# A31M22x register map
Vendor: ABOV Semiconductor Co., Ltd.; File version: 1.0
CPU: CM0PLUS r0p1, little endian, no MPU, no FPU, VTOR, 2 interrupt priority bits
Registers are 32-bit, read-write, reset 0x0 unless marked. A register's access mark holds for its fields unless they carry their own. Offsets are from the block's base; [hi:lo] are bit positions; {n}, {i} and the like mark numbered series; 'fields as' and 'values as' point back to an identical list.

## MPWM — Motor Pulse Width Modulation
Base 0x42001000
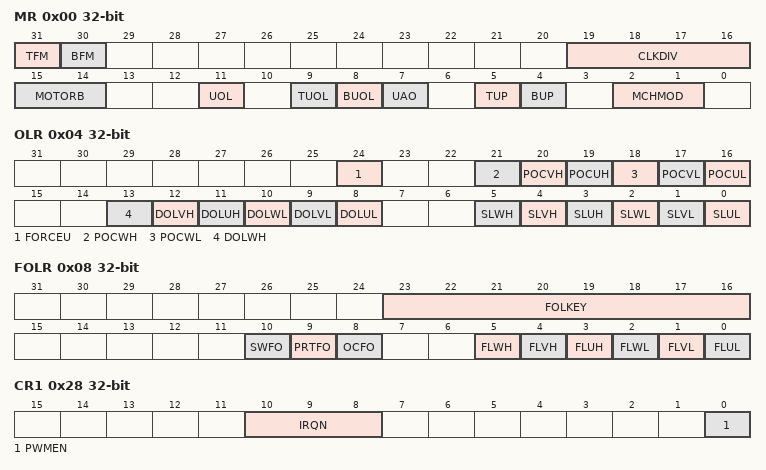
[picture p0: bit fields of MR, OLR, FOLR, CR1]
0x00 MR — MPWM Mode Register
  [31] TFM — Force Match Event at 'Full Turn Off -> PWM' in Period Match Update
    0=DISABLE (Disable force match event); 1=Enable force match event
  [30] BFM — Force Match Event at 'Full Turn On -> PWM' in Bottom Update
    values as TFM
  [19:16] CLKDIV — MPWM Clock Divider Bit, MPWM Clock = HCLK / (CLKDIV + 1)
  [15:14] MOTORB — MPWM Mode selection Bit
    0=MOTOR_PWM (Motor PWM Mode); 1=NORMAL_PWM (Normal PWM Mode)
  [11] UOL — Update Timing of Output level selection Bit
    0=DESIGNATE (Designate timing update); 1=ONCE (Once Output level Update)
  [9] TUOL — Output level Update Enable bit (When same period)
    0=None Update; 1=Update
  [8] BUOL — Output level Update Enable bit (When same bottom)
    0=None Update; 1=Update
  [7] UAO — Update Timing selection Bit
    0=DESIGNATE (Designate timing update); 1=ONCE (Once Duty Period Update)
  [5] TUP — DUTY, Period Update Enable bit (When same period)
    0=None Update; 1=Update
  [4] BUP — DUTY, Period Update Enable bit (When same bottom)
    0=None Update; 1=Update
  [2:1] MCHMOD — Channel Symmetry/Asymmetry Mode selection Bit
    0=2-ch symmetry mode; 1=1-ch asymmetry mode; 2=1-ch symmetry mode
0x04 OLR — MPWM Output Level Register
  [24] FORCEU — Phase Output selection bit
    0=6-CH (6-Channel mode); 1=Force U-Channel Mode
  [21] POCWH — PWM Output Control of WH
    0=DISABLE (PWM Output Disable); 1=ENABLE (PWM Output Enable)
  [20] POCVH — PWM Output Control of VH
    0=DISABLE (PWM Output Disable); 1=ENABLE (PWM Output Enable)
  [19] POCUH — PWM Output Control of UH
    0=DISABLE (PWM Output Disable); 1=ENABLE (PWM Output Enable)
  [18] POCWL — PWM Output Control of WL
    0=DISABLE (PWM Output Disable); 1=ENABLE (PWM Output Enable)
  [17] POCVL — PWM Output Control of VL
    0=DISABLE (PWM Output Disable); 1=ENABLE (PWM Output Enable)
  [16] POCUL — PWM Output Control of UL
    0=DISABLE (PWM Output Disable); 1=ENABLE (PWM Output Enable)
  [13] DOLWH — Output level selection bit when WH PWM Disable
    0=LOW (Low Level); 1=HIGH (High Level)
  [12] DOLVH — Output level selection bit when VH PWM Disable
    0=LOW (Low Level); 1=HIGH (High Level)
  [11] DOLUH — Output level selection bit when UH PWM Disable
    0=LOW (Low Level); 1=HIGH (High Level)
  [10] DOLWL — Output level selection bit when WL PWM Disable
    0=LOW (Low Level); 1=HIGH (High Level)
  [9] DOLVL — Output level selection bit when VL PWM Disable
    0=LOW (Low Level); 1=HIGH (High Level)
  [8] DOLUL — Output level selection bit when UL PWM Disable
    0=LOW (Low Level); 1=HIGH (High Level)
  [5] SLWH — Start Level polarity selection bit when WH PWM Start
    0=LOW (Default output level (low level)); 1=HIGH (Inverted output level (high level))
  [4] SLVH — Start Level polarity selection bit when VH PWM Start
    values as SLWH
  [3] SLUH — Start Level polarity selection bit when UH PWM Start
    values as SLWH
  [2] SLWL — Start Level polarity selection bit when WL PWM Start
    values as SLWH
  [1] SLVL — Start Level polarity selection bit when VL PWM Start
    values as SLWH
  [0] SLUL — Start Level polarity selection bit when UL PWM Start
    values as SLWH
0x08 FOLR — MPWM Forced Output Register
  [23:16] FOLKEY wo — Force output level register access key, To write a register value, the register value and the key must be used together. If the access key is not correct, the value written is ignored.
  [10] SWFO — Software force output selection bit
    0=PWM (PWM output); 1=Software (force output)
  [9] PRTFO — Protection force output bit
    0=PWM (PWM output); 1=Protection (force output)
  [8] OCFO — Over-current force output bit
    0=PWM (PWM output); 1=Over-current (force output)
  [5] FLWH — WH Force output level selection bit
    0=LOW (Force low level); 1=HIGH (Force high level)
  [4] FLVH — VH Force output level selection bit
    0=LOW (Force low level); 1=HIGH (Force level high)
  [3] FLUH — UH Force output level selection bit
    0=LOW (Force low level); 1=HIGH (Force level high)
  [2] FLWL — WL Force output level selection bit
    0=LOW (Force low level); 1=HIGH (Force level high)
  [1] FLVL — VL Force output level selection bit
    0=LOW (Force low level); 1=HIGH (Force level high)
  [0] FLUL — UL Force output level selection bit
    0=LOW (Force low level); 1=HIGH (Force level high)
0x0C PRD reset 0x2 — MPWM Period Register
  [15:0] PERIOD — 16bit pwm period
0x10 DUH reset 0x1 — MPWM DUTY UH Register
  [15:0] DUTY_UH — 16 bit PWM Duty setting bit for UH output
0x14 DVH reset 0x1 — MPWM DUTY VH Register
  [15:0] DUTY_VH — 16 bit PWM Duty setting bit for VH output
0x18 DWH reset 0x1 — MPWM DUTY WH Register
  [15:0] DUTY_WH — 16 bit PWM Duty setting bit for WH output
0x1C DUL reset 0x1 — MPWM DUTY UL Register
  [15:0] DUTY_UL — 16 bit PWM Duty setting bit for UL output
0x20 DVL reset 0x1 — MPWM DUTY VL Register
  [15:0] DUTY_VL — 16 bit PWM Duty setting bit for VL output
0x24 DWL reset 0x1 — MPWM DUTY WL Register
  [15:0] DUTY_WL — 16 bit PWM Duty setting bit for WL output
0x28 CR1 — MPWM Control Register 1
  [10:8] IRQN — IRQ number
  [0] PWMEN — PWM Enable Bit
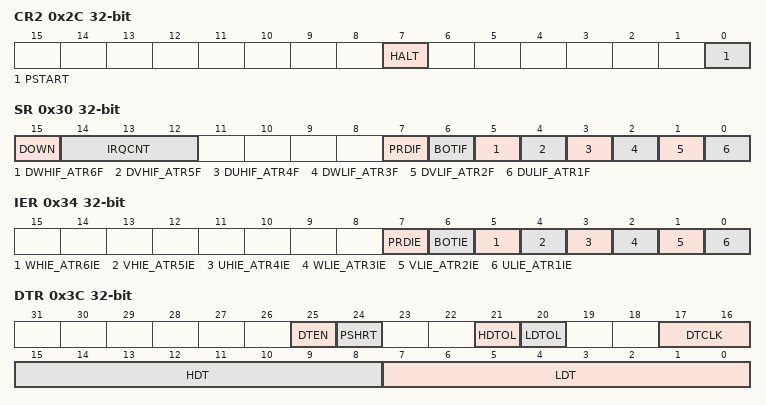
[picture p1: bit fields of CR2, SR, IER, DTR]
0x2C CR2 — MPWM Control Register 2
  [7] HALT — PWM HALT
  [0] PSTART — PWM Phase x counter start
0x30 SR — MPWM Status Register
  [15] DOWN ro — Current PWM Counter Mode
  [14:12] IRQCNT ro — Interrupt Counter Number of Period Match
  [7] PRDIF — PWM Period Interrupt Flag
  [6] BOTIF — PWM Bottom Interrupt Flag
  [5] DWHIF_ATR6F — PWM Duty Interrupt Flag (Duty Interrupt Enable when ATR6 disable)
  [4] DVHIF_ATR5F — PWM Duty Interrupt Flag (Duty Interrupt Enable when ATR6 disable)
  [3] DUHIF_ATR4F — PWM Duty Interrupt Flag (Duty Interrupt Enable when ATR6 disable)
  [2] DWLIF_ATR3F — PWM Duty Interrupt Flag (Duty Interrupt Enable when ATR6 disable)
  [1] DVLIF_ATR2F — PWM Duty Interrupt Flag (Duty Interrupt Enable when ATR6 disable)
  [0] DULIF_ATR1F — PWM Duty Interrupt Flag (Duty Interrupt Enable when ATR6 disable)
0x34 IER — MPWM Interrupt Enable Register
  [7] PRDIE — PWM Counter Period Interrupt Enable bit
  [6] BOTIE — PWM Counter Bottom Interrupt Enable bit
  [5] WHIE_ATR6IE — Duty or ATR6 Match Interrupt Enable bit
  [4] VHIE_ATR5IE — Duty or ATR5 Match Interrupt Enable bit
  [3] UHIE_ATR4IE — Duty or ATR4 Match Interrupt Enable bit
  [2] WLIE_ATR3IE — Duty or ATR3 Match Interrupt Enable bit
  [1] VLIE_ATR2IE — Duty or ATR2 Match Interrupt Enable bit
  [0] ULIE_ATR1IE — Duty or ATR1 Match Interrupt Enable bit
0x38 CNT — MPWM Counter Register
  [15:0] CNT ro — PWM Counter Value
0x3C DTR — MPWM Dead-Time Register
  [25] DTEN — Dead-time Function Enable Bit
    0=Disable dead-time function; 1=Enable dead-time function
  [24] PSHRT — Short Protecion Bit
    0=Disable short protection function; 1=Enable short protection function
  [21] HDTOL — Output level during dead-time at high side
    0=Low level during dead-time; 1=High level during dead-time
  [20] LDTOL — Output level during dead-time at low side
    0=Low level during dead-time; 1=High level during dead-time
  [17:16] DTCLK — Dead-time Prescaler Setting Bit
    0=PWMCLK_BY_2 (Dead-time counter is PWM CLK/2); 1=PWMCLK_BY_4 (Dead-time counter is PWM CLK/4); 2=PWMCLK_BY_8 (Dead-time counter is PWM CLK/8); 3=PWMCLK_BY_16 (Dead-time counter is PWM CLK/16)
  [15:8] HDT — Dead-time value at high side
  [7:0] LDT — Dead-time value at low side
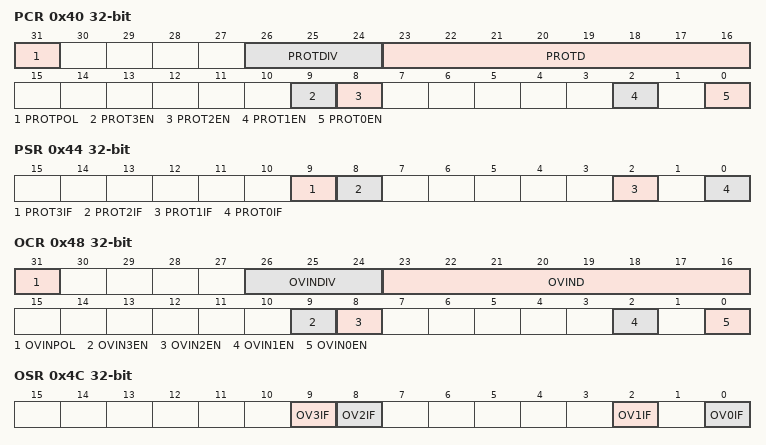
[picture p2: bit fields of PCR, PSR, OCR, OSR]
0x40 PCR — MPWM Protection Control Register
  [31] PROTPOL — PRTIN Pin Input Polarity
  [26:24] PROTDIV — PRTIN Pin Debounce Divider 2^(PROTDIV)
  [23:16] PROTD — PRTIN Pin Debounce Counter, Debounce Time = PROTD[7:0]/ (MPWMCLK/(2^(PROTDIV)))
  [9] PROT3EN — ADC CMP1 Protection Enable
  [8] PROT2EN — ADC CMP0 Protection Enable
  [2] PROT1EN — Comparator Protection Enable
  [0] PROT0EN — PRTIN Pin Protection Enable
0x44 PSR — MPWM Protection Status Register
  [9] PROT3IF — ADC CMP1 Protection Interrupt Flag
  [8] PROT2IF — ADC CMP0 Protection Interrupt Flag
  [2] PROT1IF — Comparator Protection Interrupt Flag
  [0] PROT0IF — PRTIN Pin Protection Interrupt Flag
0x48 OCR — MPWM Over Voltage Detection Register
  [31] OVINPOL — OVIN Pin Input Polarity
  [26:24] OVINDIV — OVIN Pin Debounce Divider 2^(OVINDIV)
  [23:16] OVIND — OVIN Pin Debounce Counter, Debounce Time = OVIND[7:0] / (MPWMCLK/ (2^(OVINDIV)))
  [9] OVIN3EN — ADC CMP1 Protection Enable
  [8] OVIN2EN — ADC CMP0 Protection Enable
  [2] OVIN1EN — Comparator Protection Enable
  [0] OVIN0EN — OVIN Pin Protection Enable
0x4C OSR — MPWM Over Voltage Detection Status Register
  [9] OV3IF — ADC CMP1 Protection Interrupt Flag
  [8] OV2IF — ADC CMP0 Protection Interrupt Flag
  [2] OV1IF — Comparator Protection Interrupt Flag
  [0] OV0IF — Port Over Voltage Protection Interrupt Flag
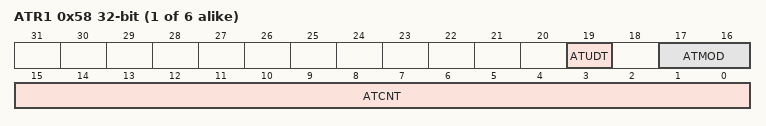
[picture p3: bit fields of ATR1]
{0x54+4i} ATR{i} (i=1..6) — MPWM ADC Trigger Counter Register
  [19] ATUDT — ADC Register Update Mode
  [17:16] ATMOD — ADC Trigger Mode selection Register
    0=Disable (ADC Trigger Disable); 1=UP_Count (Trigger out When up counter match); 2=DOWN_Count (Trigger out When down counter match); 3=UP-DOWN_Count (Trigger out When up-down counter match)
  [15:0] ATCNT — ADC Trigger Counter (only less then PWM Period)
